# AT32UC3L0128 device description
Architecture: AVR32_UC3; Family: AVR UC3
Registers are 32-bit, read-write, reset 0x0 unless marked. A register's access mark holds for its fields unless they carry their own. Offsets are from the block's base; [hi:lo] are bit positions; {n}, {i} and the like mark numbered series; 'fields as' and 'values as' point back to an identical list.

## CAT — Capacitive Touch Module
Instances: CAT 0xffff6800
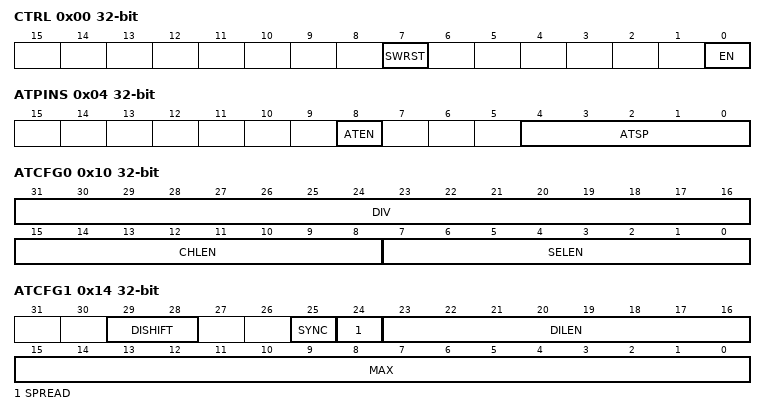
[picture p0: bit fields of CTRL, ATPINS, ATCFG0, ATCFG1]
0x00 CTRL — Control Register
  [7] SWRST — Software reset
  [0] EN — Module enable
0x04 ATPINS — Autonomous Touch Pin Selection Register
  [8] ATEN — Autonomous Touch Enable
  [4:0] ATSP — Autonomous Touch Sense Pair
0x08 PINMODE0 — Pin Mode Register 0
  [16:0] SP — Sense Pair Mode Selection
0x0C PINMODE1 — Pin Mode Register 1
  [16:0] SP — Sense Pair Mode Selection
0x10 ATCFG0 — Autonomous Touch Configuration Register 0
  [31:16] DIV — Clock Divider
  [15:8] CHLEN — Charge Length
  [7:0] SELEN — Settle Length
0x14 ATCFG1 — Autonomous Touch Configuration Register 1
  [29:28] DISHIFT — Discharge Length Shift
  [25] SYNC — Sync pin
  [24] SPREAD — Spread Spectrum Sensor Drive
  [23:16] DILEN — Touch Discharge Length
  [15:0] MAX — Maximum Count
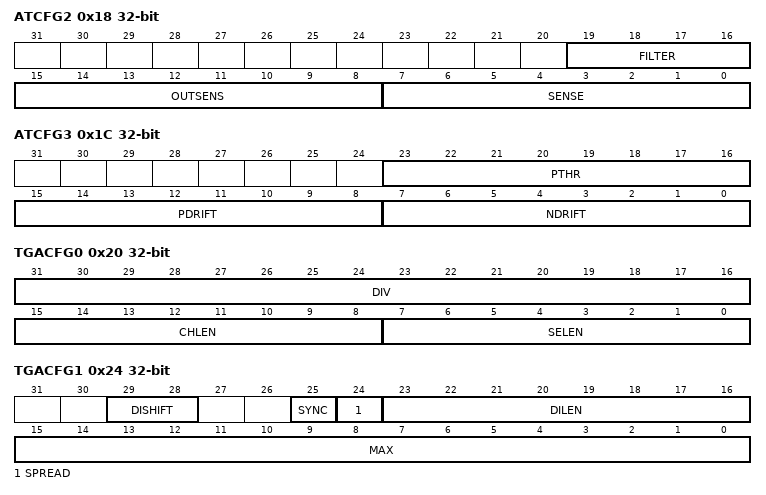
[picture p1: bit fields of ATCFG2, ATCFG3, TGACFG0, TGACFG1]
0x18 ATCFG2 — Autonomous Touch Configuration Register 2
  [19:16] FILTER — Autonomous Touch Filter Setting
  [15:8] OUTSENS — Out-of-Touch Sensitivity
  [7:0] SENSE — Sensitivity
0x1C ATCFG3 — Autonomous Touch Configuration Register 3
  [23:16] PTHR — Positive Recalibration Threshold
  [15:8] PDRIFT — Positive Drift Compensation
  [7:0] NDRIFT — Negative Drift Compensation
0x20 TGACFG0 — Touch Group A Configuration Register 0
  fields as ATCFG0
0x24 TGACFG1 — Touch Group A Configuration Register 1
  [29:28] DISHIFT — Discharge Length Shift
  [25] SYNC — Sync pin
  [24] SPREAD — Spread Spectrum Sensor Drive
  [23:16] DILEN — Touch Discharge Length
  [15:0] MAX — Touch Maximum Count
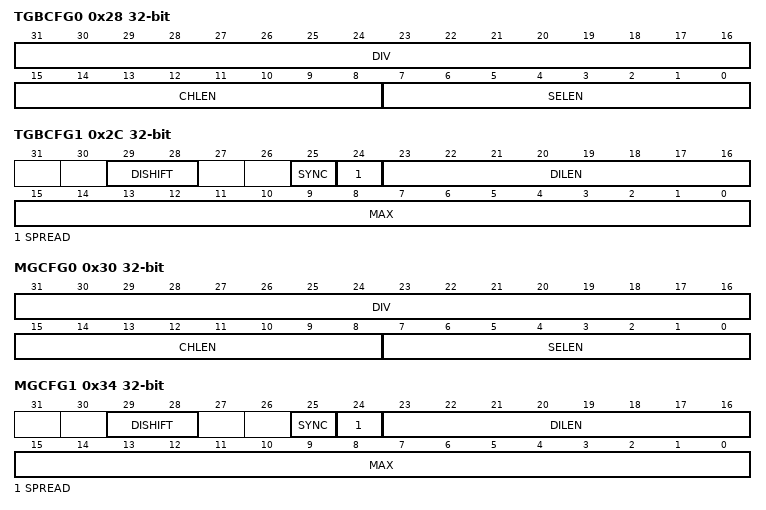
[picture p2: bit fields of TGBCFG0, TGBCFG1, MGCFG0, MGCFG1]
0x28 TGBCFG0 — Touch Group B Configuration Register 0
  fields as ATCFG0
0x2C TGBCFG1 — Touch Group B Configuration Register 1
  fields as TGACFG1
0x30 MGCFG0 — Matrix Group Configuration Register 0
  fields as ATCFG0
0x34 MGCFG1 — Matrix Group Configuration Register 1
  [29:28] DISHIFT — Discharge Length Shift
  [25] SYNC — Sync pin
  [24] SPREAD — Spread Spectrum Sensor Drive
  [23:16] DILEN — Discharge Length
  [15:0] MAX — Maximum Count
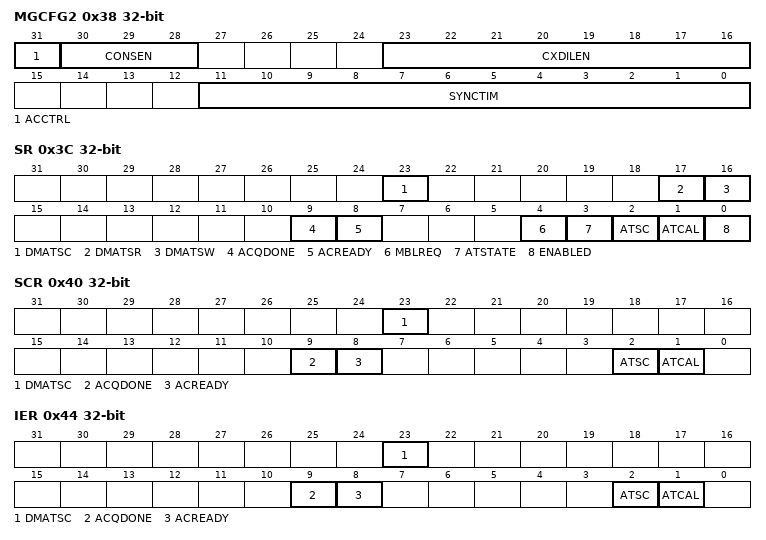
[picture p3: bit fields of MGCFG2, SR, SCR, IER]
0x38 MGCFG2 — Matrix Group Configuration Register 2
  [31] ACCTRL — Analog Comparator Control
  [30:28] CONSEN — Consensus Filter Threshold
  [23:16] CXDILEN — Cx Capacitor Discharge Length
  [11:0] SYNCTIM — Sync Time Interval
0x3C SR ro reset not defined — Status Register
  [23] DMATSC — DMATouch State Change
  [17] DMATSR — DMATouch State Read Register Ready
  [16] DMATSW — DMATouch State Write Register Request
  [9] ACQDONE — Acquisition Done
  [8] ACREADY — Acquired Count Data is Ready
  [4] MBLREQ — Matrix Burst Length Required
  [3] ATSTATE — Autonomous Touch Sensor State
  [2] ATSC — Autonomous Touch Sensor Status Interrupt
  [1] ATCAL — Autonomous Touch Calibration Ongoing
  [0] ENABLED — Module Enabled
0x40 SCR wo reset not defined — Status Clear Register
  [23] DMATSC — Clear DMATSC
  [9] ACQDONE — Clear ACQDONE
  [8] ACREADY — Clear ACREADY
  [2] ATSC — Clear ATSC
  [1] ATCAL — Clear ATCAL
0x44 IER wo reset not defined — Interrupt Enable Register
  [23] DMATSC — Enable DMATSC
  [9] ACQDONE — Enable ACQDONE
  [8] ACREADY — Enable ACREADY
  [2] ATSC — Enable ATSC
  [1] ATCAL — Enable ATCAL
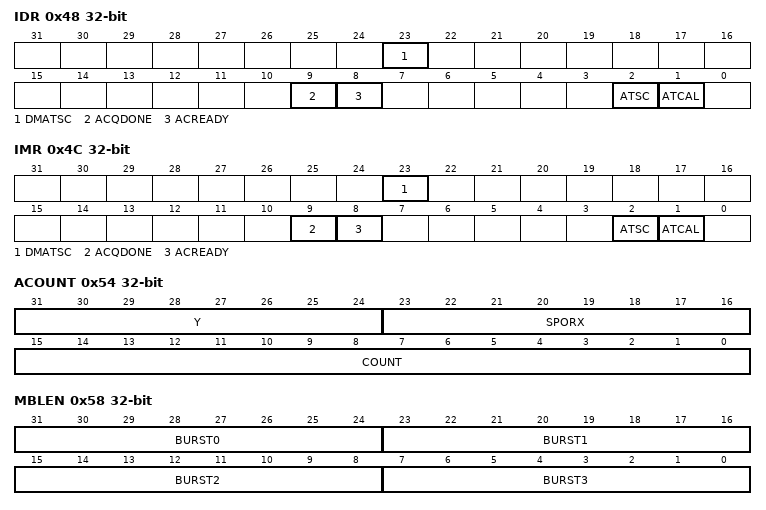
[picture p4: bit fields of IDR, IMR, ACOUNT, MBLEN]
0x48 IDR wo reset not defined — Interrupt Disable Register
  [23] DMATSC — Disable DMATSC
  [9] ACQDONE — Disable ACQDONE
  [8] ACREADY — Disable ACREADY
  [2] ATSC — Disable ATSC
  [1] ATCAL — Disable ATCAL
0x4C IMR ro — Interrupt Mask Register
  [23] DMATSC — Mask DMATSC
  [9] ACQDONE — Mask ACQDONE
  [8] ACREADY — Mask ACREADY
  [2] ATSC — Mask ATSC
  [1] ATCAL — Mask ATCAL
0x50 AISR — Acquisition Initiation and Selection Register
  [1:0] ACQSEL — Acquisition Type Selection
0x54 ACOUNT ro reset not defined — Acquired Count Register
  [31:24] Y — Y Index
  [23:16] SPORX — Sensor or X Index
  [15:0] COUNT — Count value
0x58 MBLEN wo reset not defined — Matrix Burst Length Register
  [31-8n:24-8n] BURST{n} (n=0..3) — Burst Length {n}
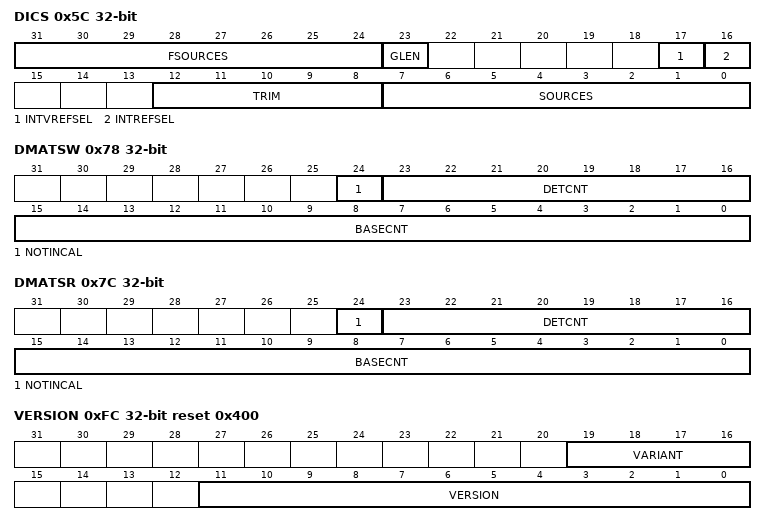
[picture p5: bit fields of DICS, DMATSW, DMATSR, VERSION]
0x5C DICS — Discharge Current Source Register
  [31:24] FSOURCES — Force Discharge Current Sources
  [23] GLEN — Global Enable Current Source Module
  [17] INTVREFSEL — Internal Voltage Reference Select
  [16] INTREFSEL — Internal Reference Select
  [12:8] TRIM — Reference Current Trimming
  [7:0] SOURCES — Enable Discharge Current Sources
0x60 SSCFG — Spread Spectrum Control Register
  [7:0] MAXDEV — Maximum Deviation
0x64 CSARES — CSA Resistor Control Register
  [16:0] RES — Resistive Drive Enable
0x68 CSBRES — CSB Resistor Control Register
  [16:0] RES — Resistive Drive Enable
0x6C ATBASE ro — Autonomous Touch Base Count Register
  [15:0] COUNT — Count Value
0x70 ATCURR ro — Autonomous Touch Current Count Register
  [15:0] COUNT — Count Value
0x74 PINMODE2 — Pin Mode Register 2
  [16:0] SP — Sense Pair Mode Selection
0x78 DMATSW wo — DMATouch State Write Register
  [24] NOTINCAL — Not in Calibration
  [23:16] DETCNT — Detection Count
  [15:0] BASECNT — Base Count
0x7C DMATSR ro — DMATouch State Read Register
  fields as DMATSW
{0x80+4i} ACSHI{i} (i=0..7) — Analog Comparator Shift {i}
  [11:0] SHIVAL — Shift value
0xA0 DMATSS ro — DMATouch Sensor Status Register
  [31:0] SS — Sensor Status
0xF8 PARAMETER ro reset not defined
  [23:0] SP — Sensor Pair Implemented
0xFC VERSION ro reset 0x400
  [19:16] VARIANT — Reserved. No functionality associated.
  [11:0] VERSION — Version number of the module. No functionality associated.
